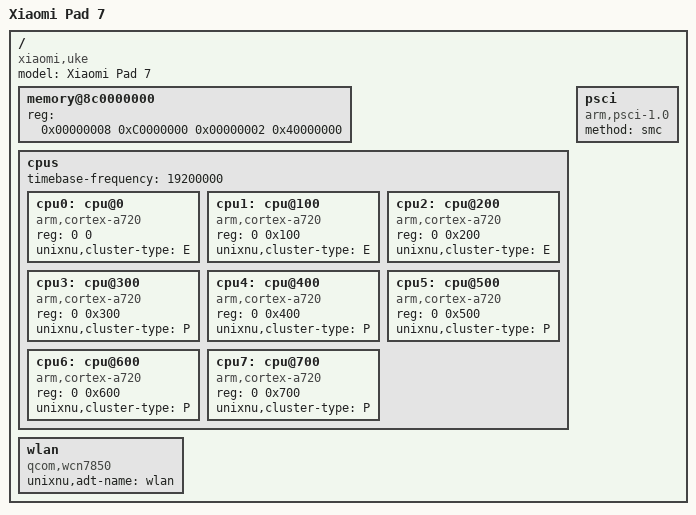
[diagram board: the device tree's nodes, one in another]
// SPDX-License-Identifier: BSD-3-Clause
// Xiaomi Pad 7 (uke, SM7675): board memory, CPUs and the hand-off nodes the
// common ADT generator turns into the Apple device tree. Shared controllers
// come from the SoC layer. Values follow the validated make-uke-adt.py output
// and the stock uke vendor_boot device tree.
/dts-v1/;
/include/ "sm7675.dtsi"

/ {
    // The generator prepends the OS identity's compatible (J120AP); these stay
    // matchable after it.
    compatible = "xiaomi,uke", "qcom,sm7675";
    model = "Xiaomi Pad 7";
    #address-cells = <2>;
    #size-cells = <2>;

    // The high DRAM window the kernel owns: base 0x8C0000000, 9 GiB. One
    // contiguous range: the ADT hand-off requires it.
    memory@8c0000000 {
        device_type = "memory";
        reg = <0x00000008 0xC0000000 0x00000002 0x40000000>;
    };

    cpus {
        #address-cells = <2>;
        #size-cells = <0>;
        timebase-frequency = <19200000>;
        // Eight Kryo cores at Affinity 0..7. The kernel's CPU topology reads
        // the compatibility string of each node.
        cpu0: cpu@0 { device_type = "cpu"; compatible = "arm,cortex-a720"; reg = <0 0>; };
        cpu1: cpu@100 { device_type = "cpu"; compatible = "arm,cortex-a720"; reg = <0 0x100>; };
        cpu2: cpu@200 { device_type = "cpu"; compatible = "arm,cortex-a720"; reg = <0 0x200>; };
        cpu3: cpu@300 { device_type = "cpu"; compatible = "arm,cortex-a720"; reg = <0 0x300>; };
        cpu4: cpu@400 { device_type = "cpu"; compatible = "arm,cortex-a720"; reg = <0 0x400>; };
        cpu5: cpu@500 { device_type = "cpu"; compatible = "arm,cortex-a720"; reg = <0 0x500>; };
        cpu6: cpu@600 { device_type = "cpu"; compatible = "arm,cortex-a720"; reg = <0 0x600>; };
        cpu7: cpu@700 { device_type = "cpu"; compatible = "arm,cortex-a720"; reg = <0 0x700>; };
    };

    psci {
        compatible = "arm,psci-1.0";
        method = "smc";
    };

    // The Wi-Fi identity 24A446's wifid waits for. Its launchd job
    // (/System/Library/LaunchDaemons/com.apple.wifid.plist in the launchd cache,
    // RunAtLoad=true, KeepAlive=true) carries
    //   _LimitLoadToDeviceTree = [wlan, marconi-wifi, centauri-alpha, centauri-alpha-protium]
    // and the check runs against this device tree, which the boot image hands the
    // kernel. Only the node name is matched; sheng's verified node is the
    // reference for the rest (chip identity string and status). Without a node
    // named wlan, wifid never starts and Settings has no Wi-Fi pane.
    wlan {
        compatible = "qcom,wcn7850";
        unixnu,adt-name = "wlan";
        status = "okay";
    };
};

// AMP/Edge requires an explicit E/P type; a missing type becomes SMP and
// cluster_type_to_pset_type() rejects it during processor_bootstrap().
// Stock uke DT: CPUs 0-2 use freq domain 0/capacity 0x400; CPUs 3-6 domain 1
// /capacity 0x69a and CPU7 domain 2/capacity 0x733. Group both faster domains
// as P, following the upstream sheng ADT binding (not the CPU compatible text).
&cpu0 { unixnu,cluster-type = "E"; };
&cpu1 { unixnu,cluster-type = "E"; };
&cpu2 { unixnu,cluster-type = "E"; };
&cpu3 { unixnu,cluster-type = "P"; };
&cpu4 { unixnu,cluster-type = "P"; };
&cpu5 { unixnu,cluster-type = "P"; };
&cpu6 { unixnu,cluster-type = "P"; };
&cpu7 { unixnu,cluster-type = "P"; };
